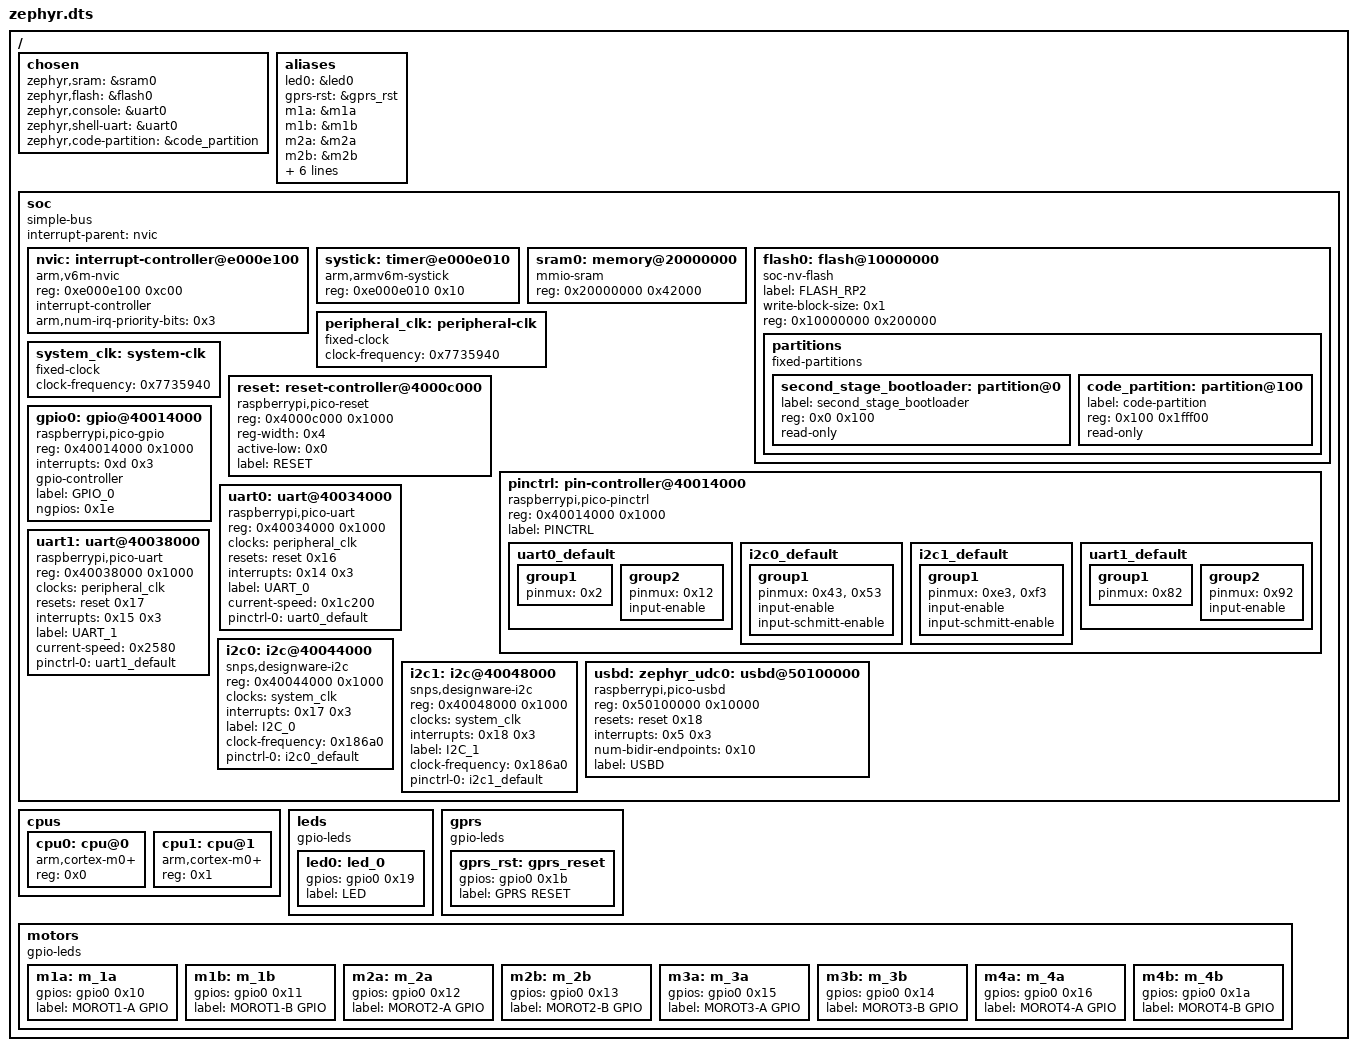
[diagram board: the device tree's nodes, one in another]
/dts-v1/;

/ {
	#address-cells = < 0x1 >;
	#size-cells = < 0x1 >;
	chosen {
		zephyr,sram = &sram0;
		zephyr,flash = &flash0;
		zephyr,console = &uart0;
		zephyr,shell-uart = &uart0;
		zephyr,code-partition = &code_partition;
	};
	aliases {
		led0 = &led0;
		gprs-rst = &gprs_rst;
		m1a = &m1a;
		m1b = &m1b;
		m2a = &m2a;
		m2b = &m2b;
		m3a = &m3a;
		m3b = &m3b;
		m4a = &m4a;
		m4b = &m4b;
		uart0 = &uart0;
		uart1 = &uart1;
	};
	soc {
		#address-cells = < 0x1 >;
		#size-cells = < 0x1 >;
		compatible = "simple-bus";
		interrupt-parent = < &nvic >;
		ranges;
		nvic: interrupt-controller@e000e100 {
			#address-cells = < 0x1 >;
			compatible = "arm,v6m-nvic";
			reg = < 0xe000e100 0xc00 >;
			interrupt-controller;
			#interrupt-cells = < 0x2 >;
			arm,num-irq-priority-bits = < 0x3 >;
			phandle = < 0x1 >;
		};
		systick: timer@e000e010 {
			compatible = "arm,armv6m-systick";
			reg = < 0xe000e010 0x10 >;
		};
		sram0: memory@20000000 {
			compatible = "mmio-sram";
			reg = < 0x20000000 0x42000 >;
		};
		flash0: flash@10000000 {
			compatible = "soc-nv-flash";
			label = "FLASH_RP2";
			write-block-size = < 0x1 >;
			reg = < 0x10000000 0x200000 >;
			partitions {
				compatible = "fixed-partitions";
				#address-cells = < 0x1 >;
				#size-cells = < 0x1 >;
				second_stage_bootloader: partition@0 {
					label = "second_stage_bootloader";
					reg = < 0x0 0x100 >;
					read-only;
				};
				code_partition: partition@100 {
					label = "code-partition";
					reg = < 0x100 0x1fff00 >;
					read-only;
				};
			};
		};
		peripheral_clk: peripheral-clk {
			compatible = "fixed-clock";
			clock-frequency = < 0x7735940 >;
			#clock-cells = < 0x0 >;
			phandle = < 0x2 >;
		};
		system_clk: system-clk {
			compatible = "fixed-clock";
			clock-frequency = < 0x7735940 >;
			#clock-cells = < 0x0 >;
			phandle = < 0x6 >;
		};
		reset: reset-controller@4000c000 {
			compatible = "raspberrypi,pico-reset";
			reg = < 0x4000c000 0x1000 >;
			reg-width = < 0x4 >;
			active-low = < 0x0 >;
			#reset-cells = < 0x1 >;
			label = "RESET";
			phandle = < 0x3 >;
		};
		pinctrl: pin-controller@40014000 {
			compatible = "raspberrypi,pico-pinctrl";
			reg = < 0x40014000 0x1000 >;
			status = "okay";
			label = "PINCTRL";
			uart0_default: uart0_default {
				phandle = < 0x4 >;
				group1 {
					pinmux = < 0x2 >;
				};
				group2 {
					pinmux = < 0x12 >;
					input-enable;
				};
			};
			i2c0_default: i2c0_default {
				phandle = < 0x7 >;
				group1 {
					pinmux = < 0x43 >, < 0x53 >;
					input-enable;
					input-schmitt-enable;
				};
			};
			i2c1_default: i2c1_default {
				phandle = < 0x8 >;
				group1 {
					pinmux = < 0xe3 >, < 0xf3 >;
					input-enable;
					input-schmitt-enable;
				};
			};
			uart1_default: uart1_default {
				phandle = < 0x5 >;
				group1 {
					pinmux = < 0x82 >;
				};
				group2 {
					pinmux = < 0x92 >;
					input-enable;
				};
			};
		};
		gpio0: gpio@40014000 {
			compatible = "raspberrypi,pico-gpio";
			reg = < 0x40014000 0x1000 >;
			interrupts = < 0xd 0x3 >;
			gpio-controller;
			#gpio-cells = < 0x2 >;
			label = "GPIO_0";
			status = "okay";
			ngpios = < 0x1e >;
			phandle = < 0x9 >;
		};
		uart0: uart@40034000 {
			compatible = "raspberrypi,pico-uart";
			reg = < 0x40034000 0x1000 >;
			clocks = < &peripheral_clk >;
			resets = < &reset 0x16 >;
			interrupts = < 0x14 0x3 >;
			interrupt-names = "uart0";
			label = "UART_0";
			status = "okay";
			current-speed = < 0x1c200 >;
			pinctrl-0 = < &uart0_default >;
			pinctrl-names = "default";
		};
		uart1: uart@40038000 {
			compatible = "raspberrypi,pico-uart";
			reg = < 0x40038000 0x1000 >;
			clocks = < &peripheral_clk >;
			resets = < &reset 0x17 >;
			interrupts = < 0x15 0x3 >;
			interrupt-names = "uart1";
			label = "UART_1";
			status = "okay";
			current-speed = < 0x2580 >;
			pinctrl-0 = < &uart1_default >;
			pinctrl-names = "default";
		};
		i2c0: i2c@40044000 {
			compatible = "snps,designware-i2c";
			#address-cells = < 0x1 >;
			#size-cells = < 0x0 >;
			reg = < 0x40044000 0x1000 >;
			clocks = < &system_clk >;
			interrupts = < 0x17 0x3 >;
			interrupt-names = "i2c0";
			label = "I2C_0";
			status = "okay";
			clock-frequency = < 0x186a0 >;
			pinctrl-0 = < &i2c0_default >;
			pinctrl-names = "default";
		};
		i2c1: i2c@40048000 {
			compatible = "snps,designware-i2c";
			#address-cells = < 0x1 >;
			#size-cells = < 0x0 >;
			reg = < 0x40048000 0x1000 >;
			clocks = < &system_clk >;
			interrupts = < 0x18 0x3 >;
			interrupt-names = "i2c1";
			label = "I2C_1";
			status = "okay";
			clock-frequency = < 0x186a0 >;
			pinctrl-0 = < &i2c1_default >;
			pinctrl-names = "default";
		};
		usbd: zephyr_udc0: usbd@50100000 {
			compatible = "raspberrypi,pico-usbd";
			reg = < 0x50100000 0x10000 >;
			resets = < &reset 0x18 >;
			interrupts = < 0x5 0x3 >;
			interrupt-names = "usbctrl";
			num-bidir-endpoints = < 0x10 >;
			label = "USBD";
			status = "okay";
		};
	};
	cpus {
		#address-cells = < 0x1 >;
		#size-cells = < 0x0 >;
		cpu0: cpu@0 {
			compatible = "arm,cortex-m0+";
			reg = < 0x0 >;
		};
		cpu1: cpu@1 {
			compatible = "arm,cortex-m0+";
			reg = < 0x1 >;
		};
	};
	leds {
		compatible = "gpio-leds";
		led0: led_0 {
			gpios = < &gpio0 0x19 0x0 >;
			label = "LED";
		};
	};
	gprs {
		compatible = "gpio-leds";
		gprs_rst: gprs_reset {
			gpios = < &gpio0 0x1b 0x0 >;
			label = "GPRS RESET";
		};
	};
	motors {
		compatible = "gpio-leds";
		m1a: m_1a {
			gpios = < &gpio0 0x10 0x0 >;
			label = "MOROT1-A GPIO";
		};
		m1b: m_1b {
			gpios = < &gpio0 0x11 0x0 >;
			label = "MOROT1-B GPIO";
		};
		m2a: m_2a {
			gpios = < &gpio0 0x12 0x0 >;
			label = "MOROT2-A GPIO";
		};
		m2b: m_2b {
			gpios = < &gpio0 0x13 0x0 >;
			label = "MOROT2-B GPIO";
		};
		m3a: m_3a {
			gpios = < &gpio0 0x15 0x0 >;
			label = "MOROT3-A GPIO";
		};
		m3b: m_3b {
			gpios = < &gpio0 0x14 0x0 >;
			label = "MOROT3-B GPIO";
		};
		m4a: m_4a {
			gpios = < &gpio0 0x16 0x0 >;
			label = "MOROT4-A GPIO";
		};
		m4b: m_4b {
			gpios = < &gpio0 0x1a 0x0 >;
			label = "MOROT4-B GPIO";
		};
	};
};
